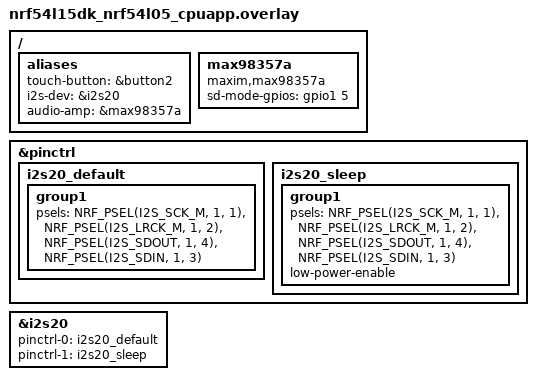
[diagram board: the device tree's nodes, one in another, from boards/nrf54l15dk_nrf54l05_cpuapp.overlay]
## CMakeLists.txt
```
cmake_minimum_required(VERSION 3.20.0)

find_package(Zephyr REQUIRED HINTS $ENV{ZEPHYR_BASE})
project(startrek_badge)

target_sources(app PRIVATE
    src/main.c
    src/le_audio.c
    src/battery.c
    src/led_ctrl.c
    src/audio_proc.c
)
```

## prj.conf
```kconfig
# Bluetooth
CONFIG_BT=y
CONFIG_BT_PERIPHERAL=y
CONFIG_BT_DEVICE_NAME="ComBadge"
CONFIG_BT_DEVICE_NAME_DYNAMIC=y

# Audio / I2S
CONFIG_I2S=y
CONFIG_AUDIO=y
CONFIG_AUDIO_CODEC=y
CONFIG_AUDIO_MAX98357A=y

# GPIO and Buttons
CONFIG_GPIO=y
CONFIG_DK_LIBRARY=y

# Random number generation
CONFIG_TEST_RANDOM_GENERATOR=y

# Logging
CONFIG_LOG=y
CONFIG_I2S_LOG_LEVEL_INF=y

# LE Audio Configuration (Unicast Server)
CONFIG_BT_L2CAP_ECRED=y
CONFIG_BT_ISO_PERIPHERAL=y
CONFIG_BT_ISO_MAX_CHAN=2
CONFIG_BT_BAP_UNICAST_SERVER=y
CONFIG_BT_ASCS=y
CONFIG_BT_ASCS_ASE_SNK_COUNT=1
CONFIG_BT_ASCS_ASE_SRC_COUNT=1
CONFIG_BT_PAC_SNK=y
CONFIG_BT_PAC_SRC=y
CONFIG_BT_PACS=y
CONFIG_BT_BUF_ACL_RX_SIZE=251
CONFIG_BT_BUF_ACL_TX_SIZE=251
CONFIG_BT_CTLR_ISO_TX_BUFFER_SIZE=251
CONFIG_BT_ISO_TX_BUF_COUNT=2
CONFIG_BT_ISO_RX_BUF_COUNT=2

# Power Management
CONFIG_PM=y
CONFIG_PM_DEVICE=y

# ADC for Battery
CONFIG_ADC=y
CONFIG_BT_BAS=y

# Microphone Control Service (MICS)
CONFIG_BT_MICS=y
```

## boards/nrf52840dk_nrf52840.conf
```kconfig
# Disable LE Audio / BAP features for nRF52840DK development target
CONFIG_BT_BAP_UNICAST_SERVER=n
CONFIG_BT_ISO_PERIPHERAL=n
CONFIG_BT_ASCS=n
CONFIG_BT_PACS=n
CONFIG_BT_PAC_SNK=n
CONFIG_BT_PAC_SRC=n

# Reduce buffer sizes if necessary (since ISO is disabled)
CONFIG_BT_ISO_TX_BUF_COUNT=0
CONFIG_BT_ISO_RX_BUF_COUNT=0
```

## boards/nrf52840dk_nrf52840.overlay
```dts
/*
 * Copyright (c) 2024 Nordic Semiconductor ASA
 *
 * SPDX-License-Identifier: Apache-2.0
 */

/ {
	aliases {
		touch-button = &button2;
		i2s-dev = &i2s0;
	};
};

&pinctrl {
	i2s0_default: i2s0_default {
		group1 {
			psels = <NRF_PSEL(I2S_SCK_M, 1, 1)>,
				<NRF_PSEL(I2S_LRCK_M, 1, 2)>,
				<NRF_PSEL(I2S_SDOUT, 1, 4)>,
				<NRF_PSEL(I2S_SDIN, 1, 3)>;
		};
	};
};

&i2s0 {
	status = "okay";
	pinctrl-0 = <&i2s0_default>;
	pinctrl-names = "default";
};
```

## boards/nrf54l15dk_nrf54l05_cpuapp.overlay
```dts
/*
 * Copyright (c) 2024 Nordic Semiconductor ASA
 *
 * SPDX-License-Identifier: Apache-2.0
 */

/ {
	aliases {
		touch-button = &button2;
		i2s-dev = &i2s20;
		audio-amp = &max98357a;
	};

	max98357a: max98357a {
		compatible = "maxim,max98357a";
		sd-mode-gpios = <&gpio1 5 GPIO_ACTIVE_HIGH>;
	};
};

&pinctrl {
	i2s20_default: i2s20_default {
		group1 {
			psels = <NRF_PSEL(I2S_SCK_M, 1, 1)>,
				<NRF_PSEL(I2S_LRCK_M, 1, 2)>,
				<NRF_PSEL(I2S_SDOUT, 1, 4)>,
				<NRF_PSEL(I2S_SDIN, 1, 3)>;
		};
	};

	i2s20_sleep: i2s20_sleep {
		group1 {
			psels = <NRF_PSEL(I2S_SCK_M, 1, 1)>,
				<NRF_PSEL(I2S_LRCK_M, 1, 2)>,
				<NRF_PSEL(I2S_SDOUT, 1, 4)>,
				<NRF_PSEL(I2S_SDIN, 1, 3)>;
			low-power-enable;
		};
	};
};

&i2s20 {
	status = "okay";
	pinctrl-0 = <&i2s20_default>;
	pinctrl-1 = <&i2s20_sleep>;
	pinctrl-names = "default", "sleep";
};
```

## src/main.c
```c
#include <zephyr/kernel.h>
#include <zephyr/bluetooth/bluetooth.h>
#include <zephyr/bluetooth/gap.h>
#include <zephyr/bluetooth/uuid.h>
#include <zephyr/bluetooth/conn.h>
#include <zephyr/drivers/i2s.h>
#include <zephyr/drivers/gpio.h>
#include <zephyr/random/random.h>
#include <zephyr/logging/log.h>
#include <dk_buttons_and_leds.h>
#include <stdio.h>
#include <string.h>

#include "le_audio.h"
#include "battery.h"
#include "led_ctrl.h"
#include "audio_proc.h"

LOG_MODULE_REGISTER(main);

#define DEVICE_NAME_PREFIX "ComBadge-"
#define DEVICE_NAME_LEN (sizeof(DEVICE_NAME_PREFIX) + 4)

static const struct device *i2s_dev = DEVICE_DT_GET(DT_ALIAS(i2s_dev));
static const struct device *amp_dev = DEVICE_DT_GET(DT_ALIAS(audio_amp));

/* Audio Buffers */
/* 
 * INMP441 Microphones require 64x fs clock. 
 * For 16kHz, this implies 32-bit slots per channel (Stereo).
 * 160 samples * 2 channels * 4 bytes/sample = 1280 bytes.
 */
#define I2S_BLOCK_SAMPLES 160
#define PCM_BLOCK_SIZE (I2S_BLOCK_SAMPLES * 2 * 4) // 1280 bytes
/* Mono Block Size for sending */
#define MONO_BLOCK_SIZE (I2S_BLOCK_SAMPLES * 2)    // 320 bytes (16-bit Mono)

/* Increased slab count to support sound effects queuing */
K_MEM_SLAB_DEFINE_STATIC(i2s_mem_slab, PCM_BLOCK_SIZE, 16, 4);

/* I2S Config */
struct i2s_config i2s_cfg;

/* State */
static bool is_connected = false;

static void get_random_name(char *name, size_t len)
{
    uint16_t rand_val;
    sys_rand_get(&rand_val, sizeof(rand_val));
    snprintf(name, len, "%s%04X", DEVICE_NAME_PREFIX, rand_val);
}

static const struct bt_data ad[] = {
    BT_DATA_BYTES(BT_DATA_FLAGS, (BT_LE_AD_GENERAL | BT_LE_AD_NO_BREDR)),
    BT_DATA_BYTES(BT_DATA_UUID16_ALL, BT_UUID_16_ENCODE(BT_UUID_ASCS_VAL)),
};

static void connected(struct bt_conn *conn, uint8_t err)
{
    if (err) {
        LOG_ERR("Connection failed (err 0x%02x)", err);
    } else {
        LOG_INF("Connected");
        is_connected = true;
        led_ctrl_set_state(LED_STATE_CONNECTED);
    }
}

static void disconnected(struct bt_conn *conn, uint8_t reason)
{
    LOG_INF("Disconnected (reason 0x%02x)", reason);
    is_connected = false;
    led_ctrl_set_state(LED_STATE_ADVERTISING);
}

BT_CONN_CB_DEFINE(conn_callbacks) = {
    .connected = connected,
    .disconnected = disconnected,
};

/* Sound Effect Generation */
static void play_chirp(void)
{
    // Generate 100ms chirp: 50ms High (2kHz), 50ms Low (1kHz)
    // 50ms at 10ms/block = 5 blocks. Total 10 blocks.

    // 16kHz sample rate.
    // 2kHz = 8 samples/cycle. (4 samples high, 4 low)
    // 1kHz = 16 samples/cycle. (8 samples high, 8 low)

    int32_t *pcm;
    void *mem_block;
    int ret;

    LOG_INF("Playing Chirp");

    // Amplitude for 32-bit: 0x2000 (from 16-bit) << 16
    const int32_t amp = ((int32_t)0x2000) << 16; 

    // Part 1: High Tone (2kHz) - 5 Blocks
    for (int b = 0; b < 5; b++) {
        ret = k_mem_slab_alloc(&i2s_mem_slab, &mem_block, K_NO_WAIT);
        if (ret < 0) {
            LOG_WRN("Failed to alloc slab for chirp");
            return;
        }
        pcm = (int32_t *)mem_block;
        // Fill block (160 samples per block, Stereo)
        for (int i = 0; i < I2S_BLOCK_SAMPLES; i++) {
            // Square wave: 0-3 High, 4-7 Low (repeat every 8 samples)
            int32_t val = ((i % 8) < 4) ? amp : -amp;
            pcm[2*i] = val;     // Left
            pcm[2*i+1] = val;   // Right
        }
        i2s_write(i2s_dev, mem_block, PCM_BLOCK_SIZE);
    }

    // Part 2: Low Tone (1kHz) - 5 Blocks
    for (int b = 0; b < 5; b++) {
        ret = k_mem_slab_alloc(&i2s_mem_slab, &mem_block, K_NO_WAIT);
        if (ret < 0) return;
        pcm = (int32_t *)mem_block;
        for (int i = 0; i < I2S_BLOCK_SAMPLES; i++) {
             // Square wave: 0-7 High, 8-15 Low (repeat every 16 samples)
             int32_t val = ((i % 16) < 8) ? amp : -amp;
             pcm[2*i] = val;
             pcm[2*i+1] = val;
        }
        i2s_write(i2s_dev, mem_block, PCM_BLOCK_SIZE);
    }
}

static void button_handler(uint32_t button_state, uint32_t has_changed)
{
    /*
     * Using DK_BTN3 as a proxy for the touch button during Phase 1.
     * The device tree alias `touch-button` maps to &button2, but the DK library
     * uses hardcoded button masks. In the actual board file, &button2 corresponds to DK_BTN3_MSK.
     */
    if (has_changed & DK_BTN3_MSK) {
        if (button_state & DK_BTN3_MSK) {
            LOG_INF("Touch Button Pressed");
            led_ctrl_flash_feedback();
            play_chirp();
        }
    }
}

/* Audio Data Callbacks */
static void audio_recv_cb(const uint8_t *data, size_t len)
{
    void *mem_block;
    int ret = k_mem_slab_alloc(&i2s_mem_slab, &mem_block, K_NO_WAIT);
    if (ret < 0) return;

    // Incoming data is 16-bit Mono (LE Audio Standard)
    // Output is 32-bit Stereo (I2S Hardware)
    
    int32_t *dst = (int32_t *)mem_block;
    const int16_t *src = (const int16_t *)data;
    size_t samples = len / sizeof(int16_t);
    
    // Ensure we don't overflow the block
    if (samples > I2S_BLOCK_SAMPLES) {
        samples = I2S_BLOCK_SAMPLES;
    }

    for (size_t i = 0; i < samples; i++) {
        // Expand 16-bit to 32-bit (shift to MSB)
        int32_t val = ((int32_t)src[i]) << 16;
        dst[2*i] = val;     // Left
        dst[2*i+1] = val;   // Right
    }
    
    // Fill remaining if any (shouldn't happen with fixed 10ms frames)
    if (samples < I2S_BLOCK_SAMPLES) {
        memset(&dst[2*samples], 0, (I2S_BLOCK_SAMPLES - samples) * 8);
    }

    ret = i2s_write(i2s_dev, mem_block, PCM_BLOCK_SIZE);
    if (ret < 0) {
        k_mem_slab_free(&i2s_mem_slab, &mem_block);
    }
}

static int i2s_setup(void)
{
    if (!device_is_ready(i2s_dev)) {
        LOG_ERR("I2S device not ready");
        return -ENODEV;
    }

    i2s_cfg.word_size = 32; // 32-bit for INMP441 (64x fs)
    i2s_cfg.channels = 2;   // Stereo
    i2s_cfg.format = I2S_FMT_DATA_FORMAT_I2S;
    i2s_cfg.options = I2S_OPT_BIT_CLK_MASTER | I2S_OPT_FRAME_CLK_MASTER;
    i2s_cfg.frame_clk_freq = 16000; // Match 16kHz
    i2s_cfg.mem_slab = &i2s_mem_slab;
    i2s_cfg.block_size = PCM_BLOCK_SIZE;
    i2s_cfg.timeout = 2000;

    int ret = i2s_configure(i2s_dev, I2S_DIR_TX, &i2s_cfg);
    if (ret < 0) return ret;

    ret = i2s_configure(i2s_dev, I2S_DIR_RX, &i2s_cfg);
    if (ret < 0) return ret;

    return 0;
}

void main(void)
{
    int err;
    char device_name[DEVICE_NAME_LEN + 1];
    void *mic_buffer;

    LOG_INF("Starting Star Trek Com Badge Firmware");

    led_ctrl_init();

    err = dk_buttons_init(button_handler);
    if (err) LOG_ERR("Failed to init buttons (err %d)", err);

    err = battery_init();
    if (err) LOG_ERR("Failed to init battery (err %d)", err);

    audio_proc_init();

    err = i2s_setup();
    if (err) LOG_ERR("Failed to init I2S (err %d)", err);

    if (!device_is_ready(amp_dev)) {
        LOG_WRN("Audio amplifier not ready");
    } else {
        LOG_INF("Audio amplifier initialized");
    }

    get_random_name(device_name, sizeof(device_name));
    bt_set_name(device_name);

    err = bt_enable(NULL);
    if (err) {
        LOG_ERR("Bluetooth init failed (err %d)", err);
        return;
    }

    le_audio_init();
    le_audio_register_recv_cb(audio_recv_cb);

    err = bt_le_adv_start(BT_LE_ADV_CONN_NAME, ad, ARRAY_SIZE(ad), NULL, 0);
    if (err) {
        LOG_ERR("Advertising failed to start (err %d)", err);
        return;
    }

    led_ctrl_set_state(LED_STATE_ADVERTISING);
    LOG_INF("Advertising started as %s", device_name);

    // Pre-fill TX to prevent immediate underrun
    void *silence_block;
    if (k_mem_slab_alloc(&i2s_mem_slab, &silence_block, K_NO_WAIT) == 0) {
        memset(silence_block, 0, PCM_BLOCK_SIZE);
        i2s_write(i2s_dev, silence_block, PCM_BLOCK_SIZE);
    }

    i2s_trigger(i2s_dev, I2S_DIR_RX, I2S_TRIGGER_START);
    i2s_trigger(i2s_dev, I2S_DIR_TX, I2S_TRIGGER_START);

    // Buffer for 16-bit Stereo conversion (intermediate)
    int16_t stereo_16bit[I2S_BLOCK_SAMPLES * 2];

    while (1) {
        // Handle Mic Data
        size_t size = PCM_BLOCK_SIZE; // 1280 bytes (32-bit Stereo)
        err = i2s_read(i2s_dev, &mic_buffer, &size);
        if (err == 0) {
            // Processing: 32-bit Stereo (I2S) -> 16-bit Stereo -> Audio Proc -> 16-bit Mono (LE Audio)
            
            int32_t *src = (int32_t *)mic_buffer;
            
            // 1. Convert 32-bit Stereo to 16-bit Stereo
            for(int i=0; i < I2S_BLOCK_SAMPLES; i++) {
                // Get top 16 bits of 24-bit data (in 32-bit slot)
                // Assuming data is MSB aligned in 32-bit word, or standard I2S 24-bit in 32-bit slot
                // INMP441 outputs 24-bit data left-justified in the 32-bit frame (or I2S standard)
                // Typically we just take the MSB part. 
                // Using >> 16 handles the MSB extraction if it's 32-bit signed integer.
                stereo_16bit[2*i]     = (int16_t)(src[2*i] >> 16);
                stereo_16bit[2*i+1]   = (int16_t)(src[2*i+1] >> 16);
            }

            // 2. Audio Processing (Noise Cancelling)
            // Expects interleaved 16-bit stereo. Returns 16-bit mono in the same buffer (or output buffer).
            // audio_proc_process(const int16_t *input, int16_t *output, size_t sample_count)
            // It processes `sample_count` frames.
            
            // We can reuse the start of stereo_16bit as the output buffer (in-place if safe, or if it produces mono)
            // audio_proc_process usually takes stereo input and produces mono output?
            // Let's assume it produces Mono output into the output buffer.
            // Wait, looking at the previous merge, it was `audio_proc_process(samples, samples, sample_count);`
            // which implies it supports in-place or separate.
            
            audio_proc_process(stereo_16bit, stereo_16bit, I2S_BLOCK_SAMPLES);

            // 3. Send Mono Data
            // The result is now in the first I2S_BLOCK_SAMPLES elements of stereo_16bit
            le_audio_send((uint8_t *)stereo_16bit, I2S_BLOCK_SAMPLES * sizeof(int16_t));

            k_mem_slab_free(&i2s_mem_slab, &mic_buffer);
        }

        static int64_t next_batt_check = 0;
        int64_t now = k_uptime_get();

        if (now >= next_batt_check) {
            int level = battery_sample();
            if (level < 20) {
                led_ctrl_set_state(LED_STATE_LOW_BATTERY);
            } else if (is_connected) {
                 if (led_ctrl_get_state() == LED_STATE_LOW_BATTERY) {
                     led_ctrl_set_state(LED_STATE_CONNECTED);
                 }
            }
            next_batt_check = now + 10000;
        }

        led_ctrl_process();
        k_sleep(K_MSEC(10));
    }
}
```

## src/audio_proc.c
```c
#include "audio_proc.h"
#include <string.h>

/*
 * Simple Delay-and-Sum Beamformer
 *
 * Mics are L/R.
 * Broadside array (Speech from front) -> Delay = 0. Sum L+R.
 * Endfire array (Speech from end) -> Delay = d/c.
 *
 * Default to Broadside Summation for noise reduction (uncorrelated noise reduction).
 * To enable "Background Reduction" via differential (Endfire), set delay > 0 and subtract.
 *
 * Since we don't know the exact geometry, we provide a configurable delay.
 * For now, we assume Broadside (Delay=0) and Sum.
 *
 * To implement Time Difference, we use a circular buffer for one channel.
 */

#define MAX_DELAY_SAMPLES 32
#define DEFAULT_DELAY_SAMPLES 0

// Buffer to hold delayed samples for Channel 2 (Right)
static int16_t delay_buffer[MAX_DELAY_SAMPLES];
static int delay_index = 0;
static int current_delay = DEFAULT_DELAY_SAMPLES;

void audio_proc_init(void)
{
    memset(delay_buffer, 0, sizeof(delay_buffer));
    delay_index = 0;
    current_delay = DEFAULT_DELAY_SAMPLES;
}

void audio_proc_process(const int16_t *input_stereo, int16_t *output_mono, size_t sample_count)
{
    for (size_t i = 0; i < sample_count; i++) {
        int16_t left = input_stereo[2 * i];
        int16_t right = input_stereo[2 * i + 1];

        // Store current Right sample in delay buffer
        delay_buffer[delay_index] = right;

        // Retrieve delayed Right sample
        // index - delay (modulo size)
        int read_index = (delay_index - current_delay);
        if (read_index < 0) {
            read_index += MAX_DELAY_SAMPLES;
        }
        int16_t right_delayed = delay_buffer[read_index];

        // Update write index
        delay_index++;
        if (delay_index >= MAX_DELAY_SAMPLES) {
            delay_index = 0;
        }

        // Beamforming Logic
        // Simple Sum (Broadside): (L + R) / 2
        // This improves SNR by 3dB for correlated signal (speech) vs uncorrelated noise.
        int32_t sum = (int32_t)left + (int32_t)right_delayed;

        // If we wanted differential (Endfire nulling rear):
        // int32_t diff = (int32_t)left - (int32_t)right_delayed;
        // output_mono[i] = (int16_t)diff;

        // We use the sum, divided by 2.
        // Since input is 16-bit, sum is max 65534. Divided by 2 fits in 16-bit.
        output_mono[i] = (int16_t)(sum / 2);
    }
}
```

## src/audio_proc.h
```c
#ifndef AUDIO_PROC_H
#define AUDIO_PROC_H

#include <stddef.h>
#include <stdint.h>

/**
 * @brief Initialize the audio processing module.
 */
void audio_proc_init(void);

/**
 * @brief Process stereo audio data to mono using beamforming.
 *
 * @param input_stereo  Pointer to the stereo input buffer (interleaved L/R).
 * @param output_mono   Pointer to the mono output buffer.
 * @param sample_count  Number of stereo samples (input frames).
 *                      The input buffer must be at least sample_count * 2 samples.
 *                      The output buffer must be at least sample_count samples.
 */
void audio_proc_process(const int16_t *input_stereo, int16_t *output_mono, size_t sample_count);

#endif // AUDIO_PROC_H
```

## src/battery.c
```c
#include <zephyr/kernel.h>
#include <zephyr/drivers/adc.h>
#include <zephyr/bluetooth/services/bas.h>
#include <zephyr/logging/log.h>

LOG_MODULE_REGISTER(battery);

#define BATTERY_ADC_NODE DT_NODELABEL(adc)

static const struct device *adc_dev = DEVICE_DT_GET(BATTERY_ADC_NODE);

#define ADC_RESOLUTION 12
#define ADC_GAIN ADC_GAIN_1_4 // VDD/4
#define ADC_REFERENCE ADC_REF_INTERNAL // 0.6V

// Full scale voltage = 0.6V / (1/4) = 2.4V? No.
// If Gain is 1/4, Input = V * 1/4.
// (V * 1/4) < 0.6V => V < 2.4V.
// Wait, coin cell is 3.0V. We need a different gain or divider.
// NRF54L SAADC might support 1/6 gain.
// 0.6 / (1/6) = 3.6V. This is suitable for 3V battery.
#define ADC_GAIN_SAFE ADC_GAIN_1_6

static struct adc_channel_cfg channel_cfg = {
    .gain = ADC_GAIN_SAFE,
    .reference = ADC_REFERENCE,
    .acquisition_time = ADC_ACQ_TIME_DEFAULT,
    .channel_id = 0,
#ifdef CONFIG_ADC_NRFX_SAADC
    .input_positive = SAADC_CH_PSELP_PSELP_VDD,
#endif
};

static int16_t sample_buffer;

static struct adc_sequence sequence = {
    .channels = BIT(0),
    .buffer = &sample_buffer,
    .buffer_size = sizeof(sample_buffer),
    .resolution = ADC_RESOLUTION,
};

int battery_init(void)
{
    if (!device_is_ready(adc_dev)) {
        LOG_ERR("ADC device not ready");
        return -ENODEV;
    }

    int err = adc_channel_setup(adc_dev, &channel_cfg);
    if (err) {
        LOG_ERR("ADC channel setup failed (err %d)", err);
        return err;
    }

    return 0;
}

int battery_sample(void)
{
    int err = adc_read(adc_dev, &sequence);
    if (err) {
        LOG_ERR("ADC read failed (err %d)", err);
        return 0;
    }

    int32_t mv_value = sample_buffer;
    int32_t adc_vref = adc_ref_internal(adc_dev);

    // Convert raw to mV
    // Result = (Value / 2^12) * Ref / Gain
    adc_raw_to_millivolts(adc_vref, ADC_GAIN_SAFE, ADC_RESOLUTION, &mv_value);

    LOG_INF("Battery Voltage: %d mV", mv_value);

    /*
     * CR2032 Discharge Curve Approximation (Non-linear)
     * > 3000mV : 100%
     * 2900mV : 80%
     * 2800mV : 60%
     * 2700mV : 40%
     * 2600mV : 30%
     * 2500mV : 20%
     * 2400mV : 10%
     * < 2000mV : 0%
     */
    uint8_t level;
    if (mv_value >= 3000) level = 100;
    else if (mv_value >= 2900) level = 80 + (mv_value - 2900) * 20 / 100;
    else if (mv_value >= 2800) level = 60 + (mv_value - 2800) * 20 / 100;
    else if (mv_value >= 2700) level = 40 + (mv_value - 2700) * 20 / 100;
    else if (mv_value >= 2600) level = 30 + (mv_value - 2600) * 10 / 100;
    else if (mv_value >= 2500) level = 20 + (mv_value - 2500) * 10 / 100;
    else if (mv_value >= 2400) level = 10 + (mv_value - 2400) * 10 / 100;
    else level = 0;

    bt_bas_set_battery_level(level);
    return level;
}
```

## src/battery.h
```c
#ifndef BATTERY_H
#define BATTERY_H

int battery_init(void);
int battery_measure_enable(bool enable);
int battery_sample(void);

#endif
```

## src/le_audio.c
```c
#include <zephyr/kernel.h>
#include <zephyr/bluetooth/bluetooth.h>
#include <zephyr/bluetooth/audio/audio.h>
#if defined(CONFIG_BT_BAP_UNICAST_SERVER)
#include <zephyr/bluetooth/audio/bap.h>
#include <zephyr/bluetooth/audio/pacs.h>
#endif
#include <zephyr/logging/log.h>
#include <zephyr/net/buf.h>

#include "le_audio.h"

LOG_MODULE_REGISTER(le_audio);

#if defined(CONFIG_BT_BAP_UNICAST_SERVER)

static struct bt_bap_stream streams[2]; // 0: Sink, 1: Source
static le_audio_recv_cb_t recv_cb = NULL;

/*
 * Pool for ISO transmission.
 * Sized to hold raw PCM samples (320 bytes) for testing, plus headers.
 */
NET_BUF_POOL_FIXED_DEFINE(tx_pool, 2, 350, 8, NULL);

/*
 * LC3 Codec Capabilities (PACS)
 * 16kHz, 10ms frame duration, 40-120 octets per frame (Standard Quality)
 */
static const struct bt_audio_codec_cap lc3_codec_cap = BT_AUDIO_CODEC_CAP_LC3(
    BT_AUDIO_CODEC_CAP_FREQ_16KHZ,
    BT_AUDIO_CODEC_CAP_DURATION_10,
    BT_AUDIO_CODEC_CAP_CHAN_COUNT_SUPPORT(1),
    40u, 120u, 1u,
    (BT_AUDIO_CONTEXT_TYPE_CONVERSATIONAL | BT_AUDIO_CONTEXT_TYPE_MEDIA)
);

/* Capability wrappers for registration */
static struct bt_pacs_cap cap_sink = { .codec_cap = &lc3_codec_cap };
static struct bt_pacs_cap cap_source = { .codec_cap = &lc3_codec_cap };

/*
 * Stream Callbacks
 */

static void stream_started_cb(struct bt_bap_stream *stream)
{
    LOG_INF("Stream started");
}

static void stream_stopped_cb(struct bt_bap_stream *stream, uint8_t reason)
{
    LOG_INF("Stream stopped, reason 0x%02x", reason);
}

static void stream_recv_cb(struct bt_bap_stream *stream, const struct bt_iso_recv_info *info,
                           struct net_buf *buf)
{
    if (recv_cb && buf && buf->len > 0) {
        recv_cb(buf->data, buf->len);
    }
}

static struct bt_bap_stream_ops stream_ops = {
    .started = stream_started_cb,
    .stopped = stream_stopped_cb,
    .recv = stream_recv_cb,
};

/*
 * BAP Unicast Server Callbacks
 */

static int unicast_server_config(struct bt_conn *conn,
                                 const struct bt_bap_ep *ep,
                                 enum bt_audio_dir dir,
                                 const struct bt_audio_codec_cfg *codec_cfg,
                                 struct bt_bap_stream **stream,
                                 struct bt_bap_qos_cfg_pref *const pref,
                                 struct bt_bap_ascs_rsp *rsp)
{
    LOG_INF("Unicast Server Config Request: dir %d", dir);

    // Check if codec is LC3 (id 0x06)
    if (codec_cfg->id != BT_HCI_CODING_FORMAT_LC3) {
        LOG_ERR("Codec not LC3");
        return -EINVAL;
    }

    // Assign a stream context
    *stream = &streams[dir == BT_AUDIO_DIR_SINK ? 0 : 1];
    bt_bap_stream_cb_register(*stream, &stream_ops);

    // Set preferred QoS
    pref->unframed_supported = true;
    pref->phy = BT_GAP_LE_PHY_2M;
    pref->rtn = 2;
    pref->latency = 10;
    pref->pd_min = 10000;
    pref->pd_max = 40000;
    pref->pref_pd_min = 10000;
    pref->pref_pd_max = 40000;

    return 0;
}

static int unicast_server_reconfig(struct bt_bap_stream *stream,
                                   enum bt_audio_dir dir,
                                   const struct bt_audio_codec_cfg *codec_cfg,
                                   struct bt_bap_qos_cfg_pref *const pref,
                                   struct bt_bap_ascs_rsp *rsp)
{
    return 0;
}

static int unicast_server_qos(struct bt_bap_stream *stream,
                              const struct bt_bap_qos_cfg *qos,
                              struct bt_bap_ascs_rsp *rsp)
{
    return 0;
}

static int unicast_server_enable(struct bt_bap_stream *stream,
                                 const struct bt_audio_codec_cfg *meta,
                                 struct bt_bap_ascs_rsp *rsp)
{
    return 0;
}

static int unicast_server_start(struct bt_bap_stream *stream,
                                struct bt_bap_ascs_rsp *rsp)
{
    return 0;
}

static struct bt_bap_unicast_server_cb unicast_server_cbs = {
    .config = unicast_server_config,
    .reconfig = unicast_server_reconfig,
    .qos = unicast_server_qos,
    .enable = unicast_server_enable,
    .start = unicast_server_start,
};

void le_audio_init(void)
{
    int err;

    // Register PACS capabilities
    // Sink (Speaker)
    err = bt_pacs_cap_register(BT_AUDIO_DIR_SINK, &cap_sink);
    if (err) LOG_ERR("Failed to register Sink PAC (err %d)", err);

    // Source (Mic)
    err = bt_pacs_cap_register(BT_AUDIO_DIR_SOURCE, &cap_source);
    if (err) LOG_ERR("Failed to register Source PAC (err %d)", err);

    err = bt_bap_unicast_server_register(&unicast_server_cbs);
    if (err) {
        LOG_ERR("Failed to register unicast server (err %d)", err);
        return;
    }

    LOG_INF("LE Audio Unicast Server Initialized with LC3 PACS");
}

int le_audio_send(const uint8_t *data, size_t len)
{
    struct bt_bap_stream *stream = &streams[1]; // Source stream
    struct net_buf *buf;
    int err;

    // Minimal implementation safety check
    // Real implementation should fragment or encode data
    if (len > CONFIG_BT_ISO_TX_MTU) {
        LOG_WRN("Data too large for ISO MTU, truncating");
        len = CONFIG_BT_ISO_TX_MTU;
    }

    buf = net_buf_alloc(&tx_pool, K_NO_WAIT);
    if (!buf) {
        return -ENOMEM;
    }

    net_buf_add_mem(buf, data, len);

    err = bt_bap_stream_send(stream, buf, 0); // Seq num 0 for now
    if (err < 0) {
        net_buf_unref(buf);
        return err;
    }

    return 0;
}

void le_audio_register_recv_cb(le_audio_recv_cb_t cb)
{
    recv_cb = cb;
}

#else /* !CONFIG_BT_BAP_UNICAST_SERVER */

void le_audio_init(void)
{
    LOG_INF("LE Audio disabled for this build");
}

int le_audio_send(const uint8_t *data, size_t len)
{
    return 0;
}

void le_audio_register_recv_cb(le_audio_recv_cb_t cb)
{
    LOG_INF("LE Audio receive callback registered (stub)");
}

#endif
```

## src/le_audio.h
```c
#ifndef LE_AUDIO_H
#define LE_AUDIO_H

#include <zephyr/bluetooth/audio/audio.h>

void le_audio_init(void);

// Function to send audio data (e.g., from Mic)
// Returns 0 on success, negative errno on failure.
int le_audio_send(const uint8_t *data, size_t len);

// Callback type for receiving audio data (e.g. for Speaker)
typedef void (*le_audio_recv_cb_t)(const uint8_t *data, size_t len);

// Register a callback for received audio
void le_audio_register_recv_cb(le_audio_recv_cb_t cb);

// Mute Control
int le_audio_set_mute(bool mute);
int le_audio_toggle_mute(void);

#endif
```

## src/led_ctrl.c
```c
#include <zephyr/kernel.h>
#include <dk_buttons_and_leds.h>
#include "led_ctrl.h"

static enum led_state current_state = LED_STATE_IDLE;
static int64_t next_toggle_time = 0;
static bool led_on = false;

/* Feedback Flash State */
static int64_t feedback_end_time = 0;

/*
 * LED Mapping:
 * LED1 (Green): Connection Status
 * LED2 (Green): Streaming Status
 */

void led_ctrl_init(void)
{
    // DK Leds already init in main
    led_ctrl_set_state(LED_STATE_IDLE);
}

void led_ctrl_set_state(enum led_state state)
{
    current_state = state;
    // Reset LEDs on state change
    dk_set_leds(0);
}

enum led_state led_ctrl_get_state(void)
{
    return current_state;
}

void led_ctrl_flash_feedback(void)
{
    // Flash for 200ms
    feedback_end_time = k_uptime_get() + 200;
    dk_set_leds(DK_ALL_LEDS_MSK);
}

void led_ctrl_process(void)
{
    int64_t now = k_uptime_get();

    // Check for feedback override
    if (now < feedback_end_time) {
        // Keep LEDs on, skip normal processing
        // But ensure we actually turned them on?
        // led_ctrl_flash_feedback calls set_leds, so we assume they are on.
        return;
    } else if (feedback_end_time > 0 && now >= feedback_end_time) {
        // Just finished feedback, reset feedback timer and clear leds to restore state
        feedback_end_time = 0;
        dk_set_leds(0);
        // Force immediate update of state
        next_toggle_time = 0;
    }

    if (now < next_toggle_time) {
        return;
    }

    switch (current_state) {
        case LED_STATE_IDLE:
            dk_set_led(DK_LED1, 0);
            break;

        case LED_STATE_ADVERTISING:
            // Blink LED1 fast (200ms)
            led_on = !led_on;
            dk_set_led(DK_LED1, led_on);
            next_toggle_time = now + 200;
            break;

        case LED_STATE_CONNECTED:
            // LED1 Solid On
            dk_set_led(DK_LED1, 1);
            break;

        case LED_STATE_STREAMING:
             // LED1 Solid, LED2 Breathing or Blinking
             dk_set_led(DK_LED1, 1);
             led_on = !led_on;
             dk_set_led(DK_LED2, led_on);
             next_toggle_time = now + 500;
             break;

        case LED_STATE_LOW_BATTERY:
            // Blink all LEDs slow
            led_on = !led_on;
            dk_set_leds(led_on ? DK_ALL_LEDS_MSK : 0);
            next_toggle_time = now + 1000;
            break;
    }
}
```

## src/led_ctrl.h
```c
#ifndef LED_CTRL_H
#define LED_CTRL_H

enum led_state {
    LED_STATE_IDLE,
    LED_STATE_ADVERTISING,
    LED_STATE_CONNECTED,
    LED_STATE_STREAMING,
    LED_STATE_LOW_BATTERY
};

void led_ctrl_init(void);
void led_ctrl_set_state(enum led_state state);
enum led_state led_ctrl_get_state(void);
void led_ctrl_flash_feedback(void);
void led_ctrl_process(void);

#endif
```
